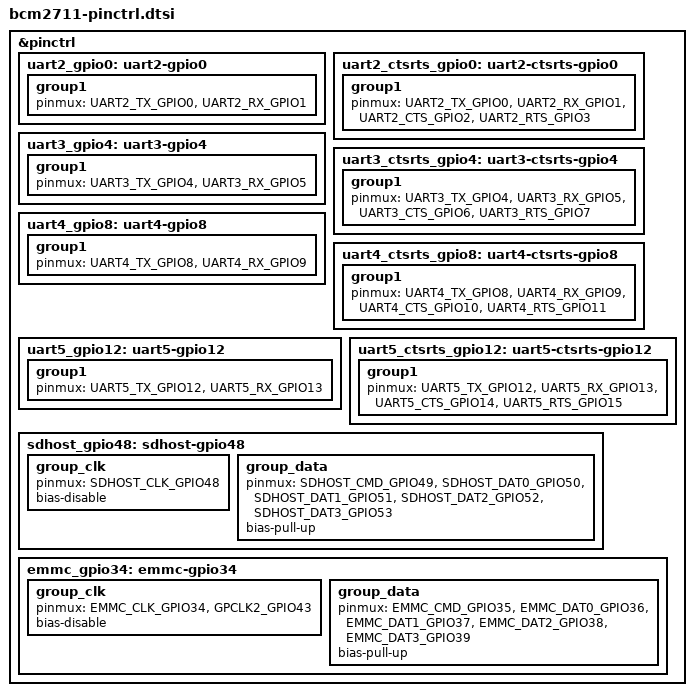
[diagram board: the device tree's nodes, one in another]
/*
 * Copyright (c) 2026 Muhammad Waleed Badar
 *
 * SPDX-License-Identifier: Apache-2.0
 */

#include <broadcom/bcm283x-pinctrl.dtsi>

&pinctrl {
	uart2_gpio0: uart2-gpio0 {
		group1 {
			pinmux = <UART2_TX_GPIO0>,
				 <UART2_RX_GPIO1>;
		};
	};

	uart2_ctsrts_gpio0: uart2-ctsrts-gpio0 {
		group1 {
			pinmux = <UART2_TX_GPIO0>,
				 <UART2_RX_GPIO1>,
				 <UART2_CTS_GPIO2>,
				 <UART2_RTS_GPIO3>;
		};
	};

	uart3_gpio4: uart3-gpio4 {
		group1 {
			pinmux = <UART3_TX_GPIO4>,
				 <UART3_RX_GPIO5>;
		};
	};

	uart3_ctsrts_gpio4: uart3-ctsrts-gpio4 {
		group1 {
			pinmux = <UART3_TX_GPIO4>,
				 <UART3_RX_GPIO5>,
				 <UART3_CTS_GPIO6>,
				 <UART3_RTS_GPIO7>;
		};
	};

	uart4_gpio8: uart4-gpio8 {
		group1 {
			pinmux = <UART4_TX_GPIO8>,
				 <UART4_RX_GPIO9>;
		};
	};

	uart4_ctsrts_gpio8: uart4-ctsrts-gpio8 {
		group1 {
			pinmux = <UART4_TX_GPIO8>,
				 <UART4_RX_GPIO9>,
				 <UART4_CTS_GPIO10>,
				 <UART4_RTS_GPIO11>;
		};
	};

	uart5_gpio12: uart5-gpio12 {
		group1 {
			pinmux = <UART5_TX_GPIO12>,
				 <UART5_RX_GPIO13>;
		};
	};

	uart5_ctsrts_gpio12: uart5-ctsrts-gpio12 {
		group1 {
			pinmux = <UART5_TX_GPIO12>,
				 <UART5_RX_GPIO13>,
				 <UART5_CTS_GPIO14>,
				 <UART5_RTS_GPIO15>;
		};
	};

	/* Legacy SDHost on GPIO 48..53 (ALT0): SDCLK / SDCMD /
	 * SDDAT0..3 for the external microSD slot. CLK is actively
	 * driven (no pull); CMD and DAT0..3 idle pulled-up between
	 * transactions.
	 */
	sdhost_gpio48: sdhost-gpio48 {
		group_clk {
			pinmux = <SDHOST_CLK_GPIO48>;
			bias-disable;
		};
		group_data {
			pinmux = <SDHOST_CMD_GPIO49>,
				 <SDHOST_DAT0_GPIO50>,
				 <SDHOST_DAT1_GPIO51>,
				 <SDHOST_DAT2_GPIO52>,
				 <SDHOST_DAT3_GPIO53>;
			bias-pull-up;
		};
	};

	/* Arasan SDHCI on GPIO 34..39 (ALT3) plus GPCLK2 on GPIO 43
	 * (ALT0): SD1_CLK / SD1_CMD / SD1_DAT0..3 + the wireless-module
	 * reference clock. CLK and GPCLK2 take no pull; CMD and DAT0..3
	 * pull-up so they idle high between transactions.
	 */
	emmc_gpio34: emmc-gpio34 {
		group_clk {
			pinmux = <EMMC_CLK_GPIO34>,
				 <GPCLK2_GPIO43>;
			bias-disable;
		};
		group_data {
			pinmux = <EMMC_CMD_GPIO35>,
				 <EMMC_DAT0_GPIO36>,
				 <EMMC_DAT1_GPIO37>,
				 <EMMC_DAT2_GPIO38>,
				 <EMMC_DAT3_GPIO39>;
			bias-pull-up;
		};
	};
};
